# A31L22x register map
Vendor: VENDOR ABOV Semiconductor Co., Ltd.; Series: A31L22x; File version: 1.0
CPU: CM0+ r0p1, little endian, no MPU, no FPU, VTOR, 2 interrupt priority bits
Registers are 32-bit, read-write, reset 0x0 unless marked. A register's access mark holds for its fields unless they carry their own. Offsets are from the block's base; [hi:lo] are bit positions; {n}, {i} and the like mark numbered series.

## TIMER4n — Timer/Counter 4n
Base 0x54000000
Same registers: TIMER41 0x40002780, TIMER42 0x40002800, TIMER43 0x40002880
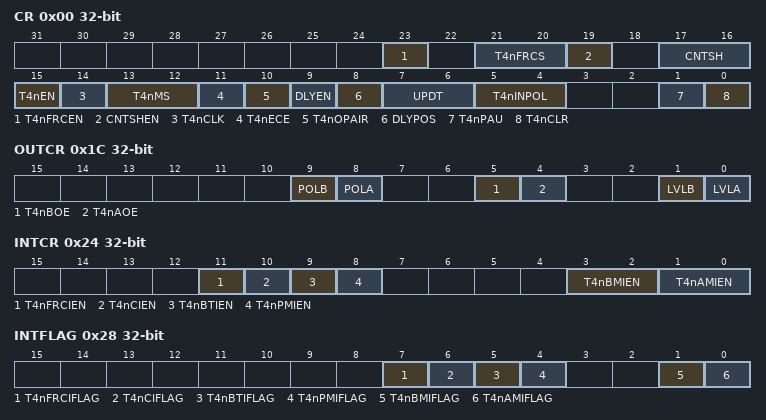
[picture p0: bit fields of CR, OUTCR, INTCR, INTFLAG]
0x00 CR — TIMER4n Control Register
  [23] T4nFRCEN — TIMER4n Output Force Level Enable
    0=Disable output force level; 1=Enable output force level during the valid level of the selected Tn force input
  [21:20] T4nFRCS — TIMER4n Force Input Selection
    {v}=T{v+40} (T{v+40} force input) (v=0..3)
  [19] CNTSHEN — Timer Counter Sharing Enable
    0=Disable counter sharing; 1=Enable counter sharing
  [17:16] CNTSH — Timer Counter Sharing Selection
    {v}=T{v+40} (Timer n uses timer {v+40}'s counter instead of itself.) (v=0..3)
  [15] T4nEN — TIMER4n Operation Enable
    0=Disable timer n operation; 1=Enable timer n operation. (Counter clear and start)
  [14] T4nCLK — TIMER4n Clock Selection
    0=IntPrescaledClock (Select the internal prescaled clock.); 1=ExtClock (Select the external clock.)
  [13:12] T4nMS — TIMER4n Operation Mode Selection
    0=Interval mode. (All match interrupts can occur); 1=Capture mode. (The Period-match interrupt can occur); 2=Back-to-back mode. (All match and bottom interrupts can occur); 3=OneShotMode (One-shot interval mode. (All match interrupts can occur))
  [11] T4nECE — TIMER4n External Clock Edge Selection
    0=FallingEdge (Select falling edge of external clock.); 1=RisingEdge (Select rising edge of external clock.)
  [10] T4nOPAIR — TIMER4n Output Pair Selection
    0=NoPair (No output pair); 1=Pair (Output pair (The TnOUTB signal depends on TIMERn_ADR register))
  [9] DLYEN — Delay Time Insertion Enable
    0=Disable to insert delay time to the TnOUTA/TnOUTB; 1=Enable to insert delay time to the TnOUTA/TnOUTB
  [8] DLYPOS — Delay Time Insertion Position
    0=FrontABackB (Insert at front of TnOUTA and at back of TnOUTB pins.); 1=BackAFrontB (Insert at back of TnOUTA and at front of TnOUTB pins.)
  [7:6] UPDT — Data Reload Time Selection
    0=AtWriting (Update data to buffer at the time of writing.); 1=AtPeriodMatch (Update data to buffer at period match.); 2=AtBottom (Update data to buffer at bottom.)
  [5:4] T4nINPOL — TIMER4n Capture/'Force level' Polarity Selection
    0=FallingEdge (Capture on falling edge, Force level on low level.); 1=RisingEdge (Capture on rising edge, Force level on high level.); 2=BothEdge (Capture on both of falling and rising edge, Not available for force level.)
  [1] T4nPAU — TIMER4n Counter Temporary Pause Control
    0=Disable (Continue counting); 1=Enable (Temporary pause)
  [0] T4nCLR — TIMER4n Counter and Prescaler Clear
    0=NoEffect; 1=Clear Counter and Prescaler. (Automatically cleared to '0' after operation)
0x04 PDR reset 0xFFFF — TIMER4n Period Data Register
  [15:0] PDATA — TIMER4n Period Data
0x08 ADR reset 0xFFFF — TIMER4n A Data Register
  [15:0] ADATA — TIMER4n A Data bits. The range is 0x0000 to 0xFFFF
0x0C BDR reset 0xFFFF — TIMER4n B Data Register
  [15:0] BDATA — TIMER4n B Data bits. The range is 0x0000 to 0xFFFF
0x10 CAPDR ro — TIMER4n Capture Data Register
  [15:0] CAPD — TIMER4n Capture Data
0x14 PREDR reset 0xFFF — TIMER4n Prescaler Data Register
  [11:0] PRED — TIMER4n Prescaler Data
0x18 CNT ro — TIMER4n Counter Register
  [15:0] CNT — TIMER4n Counter
0x1C OUTCR — TIMER4n Output Control Register
  [9] POLB — TnOUTB Output Polarity Selection
    0=StartLow (Low level start (The TnOUTB pin is started with low level after counting)); 1=StartHigh (High level start (The TnOUTB pin is started with high level after counting))
  [8] POLA — TnOUTA Output Polarity Selection
    0=StartLow (Low level start (The TnOUTA pins are started with low level after counting)); 1=StartHigh (High level start (The TnOUTA pins are started with high level after counting))
  [5] T4nBOE — TnOUTB Output Enable
    0=Disable output; 1=Enable output
  [4] T4nAOE — TnOUTA Output Enable
    0=Disable output; 1=Enable output
  [1] LVLB — Configure TnOUTB Output When Disable
    0=Low (Low level); 1=High level
  [0] LVLA — Configure TnOUTA Output When Disable
    0=Low (Low level); 1=High level
0x20 DLY — TIMER4n Output Delay Data Register
  [9:0] DLY — TIMER4n Output Delay Data
0x24 INTCR — TIMER4n Interrupt Control Register
  [11] T4nFRCIEN — TIMER4n Output Force Level Interrupt Enable
    0=Disable timer n output hold interrupt; 1=Enable timer n output hold interrupt
  [10] T4nCIEN — TIMER4n Capture Interrupt Enable
    0=Disable timer n capture interrupt; 1=Enable timer n capture interrupt
  [9] T4nBTIEN — TIMER4n Bottom Interrupt Enable
    0=Disable timer n bottom interrupt; 1=Enable timer n bottom interrupt
  [8] T4nPMIEN — TIMER4n Period Match Interrupt Enable
    0=Disable timer n period interrupt; 1=Enable timer n period interrupt
  [3:2] T4nBMIEN — TIMER4n B Match Interrupt Enable
    0=Disable B match interrupt; 1=UpCount (Enable B match interrupt on up counting.); 2=DownCount (Enable B match interrupt on down counting.); 3=BothCount (Enable B match interrupt on up and down counting.)
  [1:0] T4nAMIEN — TIMER4n A Match Interrupt Enable
    0=Disable A match interrupt; 1=UpCount (Enable A match interrupt on up counting.); 2=DownCount (Enable A match interrupt on down counting.); 3=BothCount (Enable A match interrupt on up and down counting.)
0x28 INTFLAG — TIMER4n Interrupt Flag Register
  [all] fields
    0=No request occurred; 1=Request occurred. The bit will be cleared to '0' when '1' is written to this bit.
  [7] T4nFRCIFLAG — TIMER4n Output Force Level Interrupt Flag
  [6] T4nCIFLAG — TIMER4n Capture Interrupt Flag
  [5] T4nBTIFLAG — TIMER4n Bottom Interrupt Flag
  [4] T4nPMIFLAG — TIMER4n Period Match Interrupt Flag
  [1] T4nBMIFLAG — TIMER4n B Match Interrupt Flag
  [0] T4nAMIFLAG — TIMER4n A Match Interrupt Flag
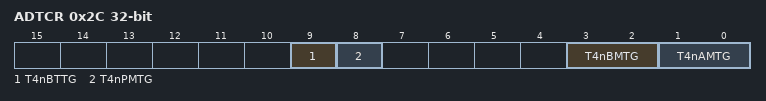
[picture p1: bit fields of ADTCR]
0x2C ADTCR — TIMER4n ADC Trigger Control Register
  [9] T4nBTTG — Select TIMER4n Bottom for ADC Trigger Signal Generator.
    0=Disable ADC trigger signal generator by bottom; 1=Enable ADC trigger signal generator by bottom
  [8] T4nPMTG — Select TIMER4n Period Match for ADC Trigger Signal Generator.
    0=Disable ADC trigger signal generator by period match; 1=Enable ADC trigger signal generator by period match
  [3:2] T4nBMTG — Select TIMER4n B Match for ADC Trigger Signal Generator.
    0=DisableUpdown (Disable ADC trigger signal generator by B match.); 1=UpCount (Enable ADC trigger signal generator by B match on up counting.); 2=DownCount (Enable ADC trigger signal generator by B match on down counting.); 3=BothCount (Enable ADC trigger signal generator by B match on up and down counting.)
  [1:0] T4nAMTG — Select TIMER4n A Match for ADC Trigger Signal Generator.
    0=Disable ADC trigger signal generator by A match; 1=UpCount (Enable ADC trigger signal generator by A match on up counting.); 2=DownCount (Enable ADC trigger signal generator by A match on down counting.); 3=BothCount (Enable ADC trigger signal generator by A match on up and down counting.)
